# STM32L152 register map
File version: 1.2
CPU: CM3 r1p1, little endian, no MPU, no FPU, 4 interrupt priority bits
Registers are 32-bit, read-write, reset 0x0 unless marked. A register's access mark holds for its fields unless they carry their own. Offsets are from the block's base; [hi:lo] are bit positions; {n}, {i} and the like mark numbered series.

## SDIO — Secure digital input/output interface
Base 0x40012C00
0x00 POWER — power control register
  [1:0] PWRCTRL — Power supply control bits.
    0=PowerOff; 3=PowerOn
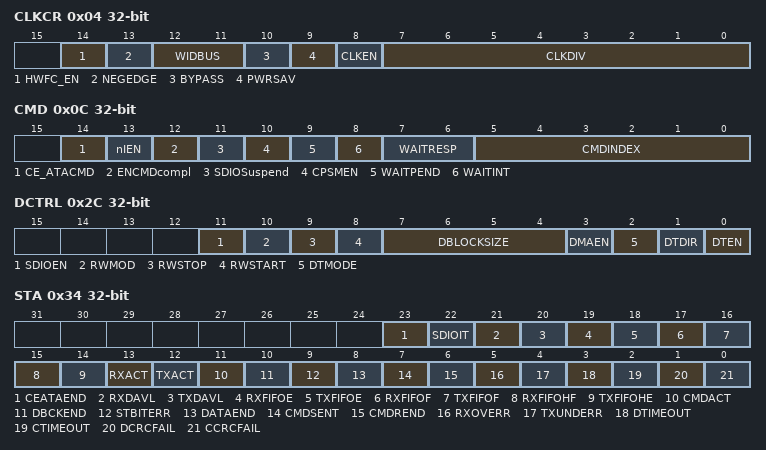
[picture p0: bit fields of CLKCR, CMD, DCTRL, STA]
0x04 CLKCR — SDI clock control register
  [14] HWFC_EN — HW Flow Control enable
    0=Disabled (HW Flow Control is disabled); 1=Enabled (HW Flow Control is enabled)
  [13] NEGEDGE — SDIO_CK dephasing selection bit
    0=Rising (SDIO_CK generated on the rising edge); 1=Falling (SDIO_CK generated on the falling edge)
  [12:11] WIDBUS — Wide bus mode enable bit
    0=BusWidth1 (1 lane wide bus); 1=BusWidth4 (4 lane wide bus); 2=BusWidth8 (8 lane wide bus)
  [10] BYPASS — Clock divider bypass enable bit
    0=Disabled (SDIOCLK is divided according to the CLKDIV value before driving the SDIO_CK output signal.); 1=Enabled (SDIOCLK directly drives the SDIO_CK output signal)
  [9] PWRSAV — Power saving configuration bit
    0=Enabled (SDIO_CK clock is always enabled); 1=Disabled (SDIO_CK is only enabled when the bus is active)
  [8] CLKEN — Clock enable bit
    0=Disabled (Disable clock); 1=Enabled (Enable clock)
  [7:0] CLKDIV — Clock divide factor
0x08 ARG — argument register
  [31:0] CMDARG — Command argument
0x0C CMD — command register
  [14] CE_ATACMD — CE-ATA command
    0=Disabled (CE-ATA command disabled); 1=Enabled (CE-ATA command enabled)
  [13] nIEN — not Interrupt Enable
    0=Disabled (Interrupts to the CE-ATA not disabled); 1=Enabled (Interrupt to the CE-ATA are disabled)
  [12] ENCMDcompl — Enable CMD completion
    0=Disabled (Command complete signal disabled); 1=Enabled (Command complete signal enabled)
  [11] SDIOSuspend — SD I/O suspend command
    0=Disabled (Next command is not a SDIO suspend command); 1=Enabled (Next command send is a SDIO suspend command)
  [10] CPSMEN — Command path state machine (CPSM) Enable bit
    0=Disabled (Command path state machine disabled); 1=Enabled (Command path state machine enabled)
  [9] WAITPEND — CPSM Waits for ends of data transfer (CmdPend internal signal).
    0=Disabled (Don't wait for data end); 1=Enabled (Wait for end of data transfer signal before sending command)
  [8] WAITINT — CPSM waits for interrupt request
    0=Disabled (Don't wait for interrupt request); 1=Enabled (Wait for interrupt request)
  [7:6] WAITRESP — Wait for response bits
    0=NoResponse; 1=ShortResponse; 2=NoResponse2 (No reponse); 3=LongResponse (Long reponse)
  [5:0] CMDINDEX — Command index
0x10 RESPCMD ro — command response register
  [5:0] RESPCMD — Response command index
{0x10+4i} RESP{i} (i=1..4) ro — SDIO response {i} register
  [31:0] CARDSTATUS — Status of a card, which is part of the received response
0x24 DTIMER — data timer register
  [31:0] DATATIME — Data timeout period
0x28 DLEN — data length register
  [24:0] DATALENGTH — Data length value
0x2C DCTRL — data control register
  [11] SDIOEN — SD I/O enable functions
    0=Disabled (SDIO operations disabled); 1=Enabled (SDIO operations enabled)
  [10] RWMOD — Read wait mode
    0=D2 (Read wait control stopping using SDIO_D2); 1=Ck (Read wait control using SDIO_CK)
  [9] RWSTOP — Read wait stop
    0=Disabled (Read wait in progress if RWSTART is enabled); 1=Enabled (Enable for read wait stop if RWSTART is enabled)
  [8] RWSTART — Read wait start
    0=Disabled (Don't start read wait operation); 1=Enabled (Read wait operation starts)
  [7:4] DBLOCKSIZE — Data block size
  [3] DMAEN — DMA enable bit
    0=Disabled (Dma disabled); 1=Enabled (Dma enabled)
  [2] DTMODE — Data transfer mode selection 1: Stream or SDIO multibyte data transfer.
    0=BlockMode (Bloack data transfer); 1=StreamMode (Stream or SDIO multibyte data transfer)
  [1] DTDIR — Data transfer direction selection
    0=ControllerToCard (From controller to card); 1=CardToController (From card to controller)
  [0] DTEN — Data transfer enabled bit
    0=Disabled; 1=Enabled (Start transfer)
0x30 DCOUNT ro — data counter register
  [24:0] DATACOUNT — Data count value
0x34 STA ro — status register
  [23] CEATAEND — CE-ATA command completion signal received for CMD61
    0=NotReceived (Completion signal not received); 1=Received (CE-ATA command completion signal received for CMD61)
  [22] SDIOIT — SDIO interrupt received
    0=NotReceived (SDIO interrupt not receieved); 1=Received (SDIO interrupt received)
  [21] RXDAVL — Data available in receive FIFO
    0=NotAvailable (Data not available in receive FIFO); 1=Available (Data available in receive FIFO)
  [20] TXDAVL — Data available in transmit FIFO
    0=NotAvailable (Data not available in transmit FIFO); 1=Available (Data available in transmit FIFO)
  [19] RXFIFOE — Receive FIFO empty
    0=NotEmpty (Receive FIFO not empty); 1=Empty (Receive FIFO empty)
  [18] TXFIFOE — Transmit FIFO empty
    0=NotEmpty (Transmit FIFO not empty); 1=Empty (Transmit FIFO empty. When HW Flow Control is enabled, TXFIFOE signals becomes activated when the FIFO contains 2 words.)
  [17] RXFIFOF — Receive FIFO full
    0=NotFull (Transmit FIFO not full); 1=Full (Receive FIFO full. When HW Flow Control is enabled, RXFIFOF signals becomes activated 2 words before the FIFO is full.)
  [16] TXFIFOF — Transmit FIFO full
    0=NotFull (Transmit FIFO not full); 1=Full (Transmit FIFO full)
  [15] RXFIFOHF — Receive FIFO half full: there are at least 8 words in the FIFO
    0=NotHalfFull (Receive FIFO not half full); 1=HalfFull (Receive FIFO half full. At least 8 words in the FIFO)
  [14] TXFIFOHE — Transmit FIFO half empty: at least 8 words can be written into the FIFO
    0=NotHalfEmpty (Transmit FIFO not half empty); 1=HalfEmpty (Transmit FIFO half empty. At least 8 words can be written into the FIFO)
  [13] RXACT — Data receive in progress
    0=NotInProgress (Data receive not in progress); 1=InProgress (Data receive in progress)
  [12] TXACT — Data transmit in progress
    0=NotInProgress (Data transmit is not in progress); 1=InProgress (Data transmit in progress)
  [11] CMDACT — Command transfer in progress
    0=NotInProgress (Command transfer not in progress); 1=InProgress (Command tranfer in progress)
  [10] DBCKEND — Data block sent/received (CRC check passed)
    0=NotTransferred (Data block not sent/received (CRC check failed)); 1=Transferred (Data block sent/received (CRC check passed))
  [9] STBITERR — Start bit not detected on all data signals in wide bus mode
    0=Detected (No start bit detected error); 1=NotDetected (Start bit not detected error)
  [8] DATAEND — Data end (data counter, SDIDCOUNT, is zero)
    0=NotDone; 1=Done (Data end (DCOUNT, is zero))
  [7] CMDSENT — Command sent (no response required)
    0=NotSent (Command not sent); 1=Sent (Command sent (no response required))
  [6] CMDREND — Command response received (CRC check passed)
    0=NotDone (Command not done); 1=Done (Command response received (CRC check passed))
  [5] RXOVERR — Received FIFO overrun error
    0=NoOverrun (No FIFO overrun error); 1=Overrun (Receive FIFO overrun error)
  [4] TXUNDERR — Transmit FIFO underrun error
    0=NoUnderrun (No transmit FIFO underrun error); 1=Underrun (Transmit FIFO underrun error)
  [3] DTIMEOUT — Data timeout
    0=NoTimeout (No data timeout); 1=Timeout (Data timeout)
  [2] CTIMEOUT — Command response timeout
    0=NoTimeout (No Command timeout); 1=Timeout (Command timeout)
  [1] DCRCFAIL — Data block sent/received (CRC check failed)
    0=NotFailed (No Data block sent/received crc check fail); 1=Failed (Data block sent/received crc failed)
  [0] CCRCFAIL — Command response received (CRC check failed)
    0=NotFailed (Command response received, crc check passed); 1=Failed (Command response received, crc check failed)
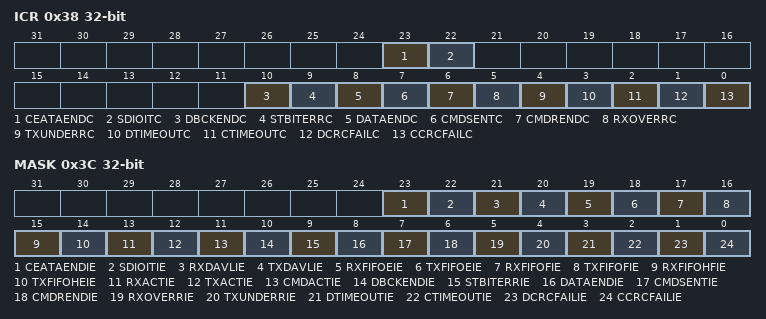
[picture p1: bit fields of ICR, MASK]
0x38 ICR — interrupt clear register
  [all] fields
    on write: 1=Clear flag
  [23] CEATAENDC — CEATAEND flag clear bit
  [22] SDIOITC — SDIOIT flag clear bit
  [10] DBCKENDC — DBCKEND flag clear bit
  [9] STBITERRC — STBITERR flag clear bit
  [8] DATAENDC — DATAEND flag clear bit
  [7] CMDSENTC — CMDSENT flag clear bit
  [6] CMDRENDC — CMDREND flag clear bit
  [5] RXOVERRC — RXOVERR flag clear bit
  [4] TXUNDERRC — TXUNDERR flag clear bit
  [3] DTIMEOUTC — DTIMEOUT flag clear bit
  [2] CTIMEOUTC — CTIMEOUT flag clear bit
  [1] DCRCFAILC — DCRCFAIL flag clear bit
  [0] CCRCFAILC — CCRCFAIL flag clear bit
0x3C MASK
  [all] fields
    0=Disabled (Interrupt disabled); 1=Enabled (Interrupt enabled)
  [23] CEATAENDIE — CE-ATA command completion signal received interrupt enable
  [22] SDIOITIE — SDIO mode interrupt received interrupt enable
  [21] RXDAVLIE — Data available in Rx FIFO interrupt enable
  [20] TXDAVLIE — Data available in Tx FIFO interrupt enable
  [19] RXFIFOEIE — Rx FIFO empty interrupt enable
  [18] TXFIFOEIE — Tx FIFO empty interrupt enable
  [17] RXFIFOFIE — Rx FIFO full interrupt enable
  [16] TXFIFOFIE — Tx FIFO full interrupt enable
  [15] RXFIFOHFIE — Rx FIFO half full interrupt enable
  [14] TXFIFOHEIE — Tx FIFO half empty interrupt enable
  [13] RXACTIE — Data receive acting interrupt enable
  [12] TXACTIE — Data transmit acting interrupt enable
  [11] CMDACTIE — Command acting interrupt enable
  [10] DBCKENDIE — Data block end interrupt enable
  [9] STBITERRIE — Start bit error interrupt enable
  [8] DATAENDIE — Data end interrupt enable
  [7] CMDSENTIE — Command sent interrupt enable
  [6] CMDRENDIE — Command response received interrupt enable
  [5] RXOVERRIE — Rx FIFO overrun error interrupt enable
  [4] TXUNDERRIE — Tx FIFO underrun error interrupt enable
  [3] DTIMEOUTIE — Data timeout interrupt enable
  [2] CTIMEOUTIE — Command timeout interrupt enable
  [1] DCRCFAILIE — Data CRC fail interrupt enable
  [0] CCRCFAILIE — Command CRC fail interrupt enable
0x48 FIFOCNT ro — FIFO counter register
  [23:0] FIFOCOUNT — Remaining number of words to be written to or read from the FIFO.
0x80 FIFO — data FIFO register
  [31:0] FIFOData — FIF0Data
